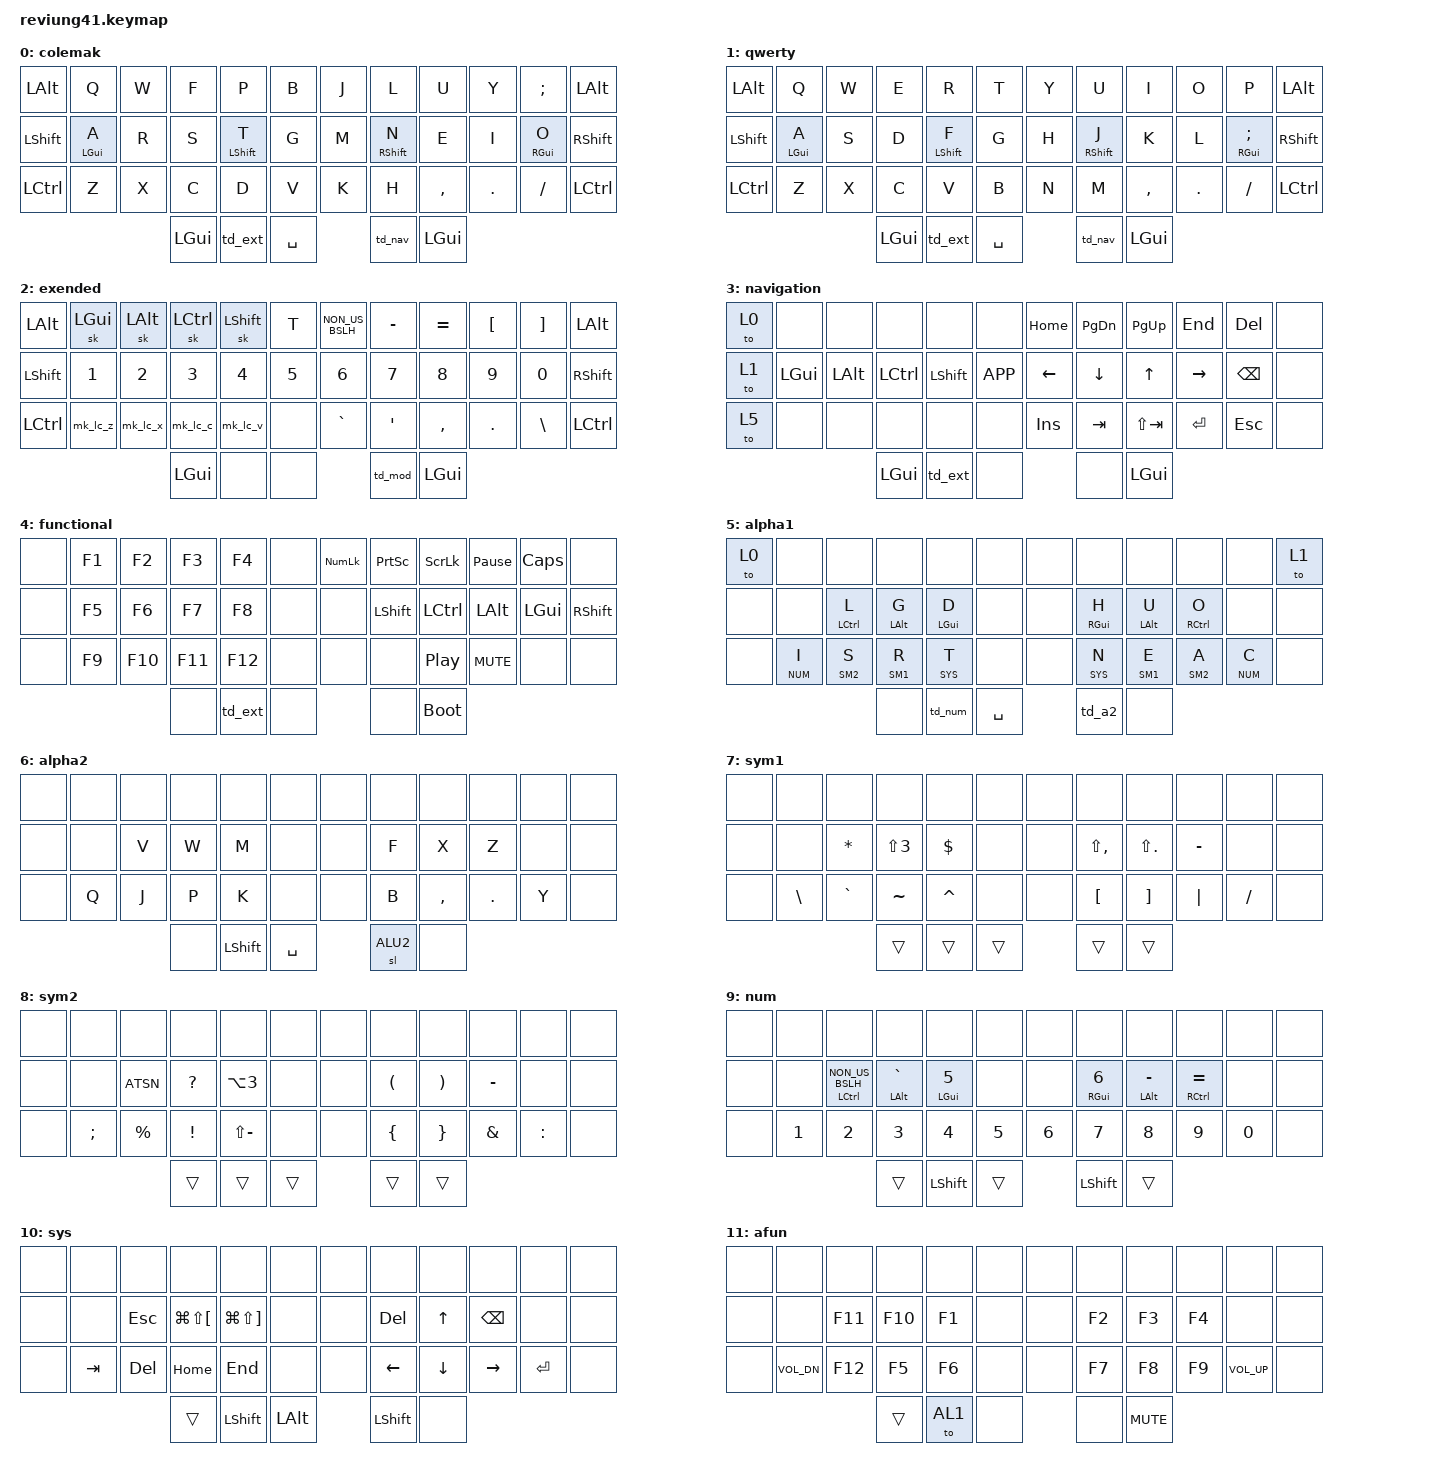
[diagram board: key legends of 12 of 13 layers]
/*
 * Copyright (c) 2020 The ZMK Contributors
 *
 * SPDX-License-Identifier: MIT
 */
/* THIS FILE WAS GENERATED!
 *
 * This file was generated automatically. You may or may not want to
 * edit it directly.
 */

#include <behaviors.dtsi>
#include <dt-bindings/zmk/keys.h>

 &mt {
     tapping-term-ms = <201>;
     flavor = "tap-preferred";
  };
 &sk {
      release-after-ms = <2000>;
      quick-release;
  };
 
#define LCOL   0
#define LQWE   1
#define LEXT   2
#define LNAV   3
#define LFUN   4

#define AL1 5
#define AL2 6
#define SM1 7
#define SM2 8
#define NUM 9
#define SYS 10
#define AFUN 11
#define ALU2 12

#define _____ &none

/ {
    combos {
        compatible = "zmk,combos";

        lock {
            bindings = <&kp LG(L)>;
            key-positions = <11 23 35>;
            layers = <0 1>;
            timeout-ms = <50>;
        };

        right_escape {
            bindings = <&kp ESC>;
            key-positions = <8 9>;
            timeout-ms = <20>;
            layers = <0 1>;
        };

        right_enter {
            bindings = <&kp ENTER>;
            key-positions = <20 21>;
            timeout-ms = <20>;
            layers = <0 1>;
        };

        left_escape {
            bindings = <&kp ESC>;
            key-positions = <2 3>;
            timeout-ms = <20>;
            layers = <0 1>;
        };

        left_enter {
            bindings = <&kp ENTER>;
            key-positions = <14 15>;
            timeout-ms = <20>;
            layers = <0 1>;
        };

        al_enter {
            bindings = <&kp ENTER>;
            key-positions = <32 33>;
            timeout-ms = <20>;
            layers = < AL1 >;
        };

        al_escape {
            bindings = <&kp ESC>;
            key-positions = <20 21>;
            timeout-ms = <20>;
            layers = < AL1 >;
        };
    };

    macros {
        to_eng: to_eng {
            label = "to_eng";
            compatible = "zmk,behavior-macro";
            #binding-cells = <0>;
            bindings = <&to LCOL &kp LC(LS(N1))>;
        };
        to_rus: to_rus {
            label = "to_rus";
            compatible = "zmk,behavior-macro";
            #binding-cells = <0>;
            bindings = <&to LQWE &kp LC(LS(N2))>;
        };
        mk_shifted: mk_shifted {
            label = "mk_shifted";
            compatible = "zmk,behavior-macro";
            #binding-cells = <0>;
            wait-ms = <0>;
            bindings =
                <&macro_press>,
                <&mo LEXT &kp LSHFT>,
                <&macro_pause_for_release>,
                <&macro_release>,
                <&mo LEXT &kp LSHFT>;
        };
        ZMK_MACRO(mk_lc_z,
            wait-ms = <30>;
            tap-ms = <40>;
            bindings = <&macro_press &kp LCTRL>, <&macro_tap &kp Z>, <&macro_release &kp LCTRL>;
        )
        ZMK_MACRO(mk_lc_x,
            wait-ms = <30>;
            tap-ms = <40>;
            bindings = <&macro_press &kp LCTRL>, <&macro_tap &kp X>, <&macro_release &kp LCTRL>;
        )
        ZMK_MACRO(mk_lc_c,
            wait-ms = <30>;
            tap-ms = <40>;
            bindings = <&macro_press &kp LCTRL>, <&macro_tap &kp C>, <&macro_release &kp LCTRL>;
        )
        ZMK_MACRO(mk_lc_v,
            wait-ms = <30>;
            tap-ms = <40>;
            bindings = <&macro_press &kp LCTRL>, <&macro_tap &kp V>, <&macro_release &kp LCTRL>;
        )
    };

    behaviors {
        td_nav: tap_dance_nav {
            compatible = "zmk,behavior-tap-dance";
            label = "TAP_DANCE_NAV";
            #binding-cells = <0>;
            tapping-term-ms = <200>;
            bindings =
                <&mo LNAV>,
                <&mo LFUN>;
        };
        td_ext: tap_dance_ext {
            compatible = "zmk,behavior-tap-dance";
            label = "TAP_DANCE_EXT";
            #binding-cells = <0>;
            tapping-term-ms = <200>;
            bindings =
                <&mo LEXT>,
                <&mk_shifted>,
                <&mo LNAV>;
        };
        td_mod: tap_dance_mod {
            compatible = "zmk,behavior-tap-dance";
            label = "TAP_DANCE_MOD";
            #binding-cells = <0>;
            tapping-term-ms = <200>;
            bindings =
                <&kp LSHFT>,
                <&kp LCTRL>;
        };
        lmt: left_hand_positional_hold_tap {
            compatible = "zmk,behavior-hold-tap";
            label = "LEFT_POSITIONAL_HOLD_TAP";
            #binding-cells = <2>;
            flavor = "balanced";
            tapping-term-ms = <500>;                        // <---[[produces tap if held longer than tapping-term-ms]]
            quick-tap-ms = <250>;
            bindings = <&kp>, <&kp>;
            hold-trigger-key-positions = < 6 7 8 9 10 11 18 19 20 21 22 23 30 31 32 33 34 35>;    // <---[[right-hand keys]]
        };
        rmt: right_hand_positional_hold_tap {
            compatible = "zmk,behavior-hold-tap";
            label = "RIGHT_POSITIONAL_HOLD_TAP";
            #binding-cells = <2>;
            flavor = "balanced";
            tapping-term-ms = <500>;                        // <---[[produces tap if held longer than tapping-term-ms]]
            quick-tap-ms = <250>;
            bindings = <&kp>, <&kp>;
            hold-trigger-key-positions = < 0 1 2 3 4 5 12 13 14 15 16 17 24 25 26 27 28 29 >;    // <---[[left-hand keys]]
        };

        sr: shift_layer {
            compatible = "zmk,behavior-hold-tap";
            label = "SHIFT_LAYER";
            #binding-cells = <2>;
            tapping-term-ms = <300>;
            quick_tap_ms = <0>;
            flavor = "tap-preferred";
            bindings = <&kp>, <&to>;
        retro-tap;
        };
        hl_l: homerow_layers_left {
            compatible = "zmk,behavior-hold-tap";
            label = "HOMEROW_LAYERS_L";
            #binding-cells = <2>;
            tapping-term-ms = <220>;
            quick-tap-ms = <250>;
            flavor = "tap-preferred";
            bindings = <&mo>, <&kp>;
            hold-trigger-key-positions = < 6 7 8 9 10 11 18 19 20 21 22 23 30 31 32 33 34 35>;    // <---[[right-hand keys]]
        };
        hl_r: homerow_layers_right {
            compatible = "zmk,behavior-hold-tap";
            label = "HOMEROW_LAYERS_R";
            #binding-cells = <2>;
            tapping-term-ms = <220>;
            quick-tap-ms = <250>;
            flavor = "tap-preferred";
            bindings = <&mo>, <&kp>;
            hold-trigger-key-positions = < 0 1 2 3 4 5 12 13 14 15 16 17 24 25 26 27 28 29 >;    // <---[[left-hand keys]]
        };

        alpha2macro: behavior_macro_1 {
            compatible = "zmk,behavior-macro";
            label = "MACRO1";
            #binding-cells = <0>;
            bindings = < &sl AL2 >;
        };
        caps_alpha2macro: behavior_macro_2 {
            compatible = "zmk,behavior-macro";
            label = "MACRO2";
            #binding-cells = <0>;
            bindings = < &sl ALU2 >;
        };
        td_a2: tap_dance_a2 {
            compatible = "zmk,behavior-tap-dance";
            label = "TAP_DANCE_A2";
            #binding-cells = <0>;
            tapping-term-ms = <200>;
            bindings =
                < &sl AL2  >,
                < &sl ALU2 >;
        };
        td_num: tap_dance_num {
            compatible = "zmk,behavior-tap-dance";
            label = "TAP_DANCE_NUM";
            #binding-cells = <0>;
            tapping-term-ms = <200>;
            bindings =
                < &kp LSHFT >,
                < &sl NUM >;
        };

    };

    keymap {
        compatible = "zmk,keymap";

        colemak {
            bindings = <
    &kp LALT   &kp Q        &kp W    &kp F     &kp P         &kp B            &kp J      &kp L          &kp U      &kp Y    &kp SEMI     &kp LALT
    &kp LSHFT  &lmt LGUI A  &kp R    &kp S     &lmt LSHFT T  &kp G            &kp M      &rmt RSHFT N   &kp E      &kp I    &rmt RGUI O  &kp RSHFT
    &kp LCTRL  &kp Z        &kp X    &kp C     &kp D         &kp V            &kp K      &kp H          &kp COMMA  &kp DOT  &kp FSLH     &kp LCTRL
                                     &kp LGUI  &td_ext              &kp SPACE            &td_nav        &kp LGUI
            >;
        };
        
        qwerty {
            bindings = <
    &kp LALT   &kp Q        &kp W   &kp E     &kp R         &kp T            &kp Y       &kp U         &kp I      &kp O     &kp P           &kp LALT
    &kp LSHFT  &lmt LGUI A  &kp S   &kp D     &lmt LSHFT F  &kp G            &kp H       &rmt RSHFT J  &kp K      &kp L     &rmt RGUI SEMI  &kp RSHFT
    &kp LCTRL  &kp Z        &kp X   &kp C     &kp V         &kp B            &kp N       &kp M         &kp COMMA  &kp DOT   &kp FSLH        &kp LCTRL
                                    &kp LGUI  &td_ext              &kp SPACE             &td_nav       &kp LGUI
            >;
        };

        exended {
            bindings = <
    &kp LALT   &sk LGUI  &sk LALT  &sk LCTRL  &sk LSHFT &kp T      &kp NON_US_BSLH  &kp MINUS  &kp EQUAL  &kp LBKT  &kp RBKT  &kp LALT
    &kp LSHFT  &kp N1    &kp N2    &kp N3     &kp N4    &kp N5     &kp N6           &kp N7     &kp N8     &kp N9    &kp N0    &kp RSHFT
    &kp LCTRL  &mk_lc_z  &mk_lc_x  &mk_lc_c   &mk_lc_v  _____      &kp GRAVE        &kp SQT    &kp COMMA  &kp DOT   &kp BSLH  &kp LCTRL
                                   &kp LGUI   _____          _____                  &td_mod    &kp LGUI
            >;
        };

        navigation {
            bindings = <
    &to 0   _____     _____     _____      _____       _____         &kp HOME   &kp PG_DN  &kp PG_UP    &kp END    &kp DEL   _____
    &to 1   &kp LGUI  &kp LALT  &kp LCTRL  &kp LSHIFT  &kp K_APP     &kp LEFT   &kp DOWN   &kp UP       &kp RIGHT  &kp BSPC  _____
    &to 5   _____     _____     _____      _____       _____         &kp INS    &kp TAB    &kp LS(TAB)  &kp ENTER  &kp ESC   _____
                                &kp LGUI   &td_ext             _____            _____      &kp LGUI
            >;
        };

        functional {
            bindings = <
    _____      &kp F1  &kp F2   &kp F3   &kp F4    _____          &kp KP_NUMLOCK  &kp PRINTSCREEN   &kp SCROLLLOCK    &kp PAUSE_BREAK  &kp CAPS  _____
    _____      &kp F5  &kp F6   &kp F7   &kp F8    _____          _____           &kp LSHFT         &kp LCTRL         &kp LALT         &kp LGUI  &kp RSHFT
    _____      &kp F9  &kp F10  &kp F11  &kp F12   _____          _____           _____             &kp C_PLAY_PAUSE  &kp C_MUTE       _____     _____
                                _____    &td_ext          _____                   _____             &bootloader
            >;
        };

// ==================================================================================================================================================================
                
        alpha1 {
            bindings = <
                &to 0     _____        _____        _____        _____        _____            _____   _____        _____        _____        _____        &to 1
                _____     _____        &lmt LCTL L  &lmt LALT G  &lmt LGUI D  _____            _____   &rmt RGUI H  &rmt LALT U  &rmt RCTL O  _____        _____
                _____     &hl_l NUM I  &hl_l SM2 S  &hl_l SM1 R  &hl_l SYS T  _____            _____   &hl_r SYS N  &hl_r SM1 E  &hl_r SM2 A  &hl_r NUM C  _____
                                                    _____        &td_num             &kp SPC           &td_a2       _____
            >;
        };

        alpha2 {
            bindings = <
                _____     _____        _____        _____        _____        _____            _____   _____        _____        _____        _____        _____
                _____     _____        &kp V        &kp W        &kp M        _____            _____   &kp F        &kp X        &kp Z        _____        _____   
                _____     &kp Q        &kp J        &kp P        &kp K        _____            _____   &kp B        &kp COMMA    &kp DOT      &kp Y        _____
                                                    _____        &kp LSHIFT           &kp SPC          &sl ALU2     _____    
            >;
        };

        sym1 {
            bindings = <
                _____     _____        _____        _____        _____        _____            _____   _____          _____        _____      _____       _____
                _____     _____        &kp STAR     &kp LS(N3)   &kp DLLR     _____            _____   &kp LS(COMMA)  &kp LS(DOT)  &kp MINUS  _____       _____     
                _____     &kp BSLH     &kp GRAVE    &kp TILDE    &kp CARET    _____            _____   &kp LBKT       &kp RBKT     &kp PIPE   &kp SLASH   _____
                                                    &trans       &trans               &trans           &trans         &trans
            >;
        };
        
        sym2 {
            bindings = <
                _____     _____        _____        _____        _____         _____           _____   _____         _____        _____        _____      _____
                _____     _____        &kp ATSN     &kp QMARK    &kp LA(N3)    _____           _____   &kp LPRN      &kp RPRN     &kp MINUS    _____      _____     
                _____     &kp SEMI     &kp PRCNT    &kp EXCL     &kp LS(MINUS) _____           _____   &kp LBRC      &kp RBRC     &kp AMPS     &kp COLON  _____
                                                    &trans       &trans               &trans           &trans         &trans
            >;
        };

        // num {
        //     bindings = <
        //         _____     _____        _____           _____         _____         _____       _____   _____          _____          _____          _____      _____
        //         _____     _____        &lmt LCTL DOT   &lmt LALT N0  &lmt LGUI N1  _____       _____   &rmt RGUI N2   &rmt LALT N3   &rmt RCTL N4   _____      _____
        //         _____     &kp MINUS    &kp PLUS        &kp N5        &kp N6        _____       _____   &kp N7         &kp N8         &kp N9         &kp EQUAL  _____ 
        //                                                &trans        &sr LSHIFT AL1      &trans        &trans         &kp RGUI
        // >;
        // };

        num {
            bindings = <
                _____     _____     _____                  _____            _____         _____        _____   _____          _____            _____            _____      _____
                _____     _____     &lmt LCTL NON_US_BSLH  &lmt LALT GRAVE  &lmt LGUI N5  _____        _____   &rmt RGUI N6   &rmt LALT MINUS  &rmt RCTL EQUAL  _____      _____
                _____     &kp N1    &kp N2                 &kp N3           &kp N4        &kp N5       &kp N6  &kp N7         &kp N8           &kp N9           &kp N0     _____ 
                                                           &trans           &kp LSHIFT          &trans         &kp LSHIFT     &trans
            >;
        };

        sys {
            bindings = <
                _____     _____    _____    _____             _____             _____           _____   _____       _____     _____      _____    _____
                _____     _____    &kp ESC  &kp LG(LS(LBKT))  &kp LG(LS(RBKT))  _____           _____   &kp DEL     &kp UP    &kp BKSP   _____    _____
                _____     &kp TAB  &kp DEL  &kp HOME          &kp END           _____           _____   &kp LEFT    &kp DOWN  &kp RIGHT  &kp RET  _____
                                            &trans            &kp LSHIFT              &kp LALT          &kp LSHIFT  _____
            >;
        };

        afun {
            bindings = <
                _____     _____         _____    _____    _____   _____         _____   _____    _____    _____   _____         _____
                _____     _____         &kp F11  &kp F10  &kp F1  _____         _____   &kp F2   &kp F3   &kp F4  _____         _____     
                _____     &kp C_VOL_DN  &kp F12  &kp F5   &kp F6  _____         _____   &kp F7   &kp F8   &kp F9  &kp C_VOL_UP  _____
                                        &trans   &to AL1                 _____          _____    &kp C_MUTE
            >;
        };

        alpha2cap {
            bindings = <
                _____     _____      _____      _____      _____      _____         _____  _____      _____       _____      _____      _____
                _____     _____      &kp LS(V)  &kp LS(W)  &kp LS(M)  _____         _____  &kp LS(F)  &kp LS(X)   &kp LS(Z)  _____      _____
                _____     &kp LS(Q)  &kp LS(J)  &kp LS(P)  &kp LS(K)  _____         _____  &kp LS(B)  &kp LBKT    &kp RBKT   &kp LS(Y)  _____
                                     &trans     &kp LSHIFT                  &trans         &trans     _____
            >;
        };

    };
};
